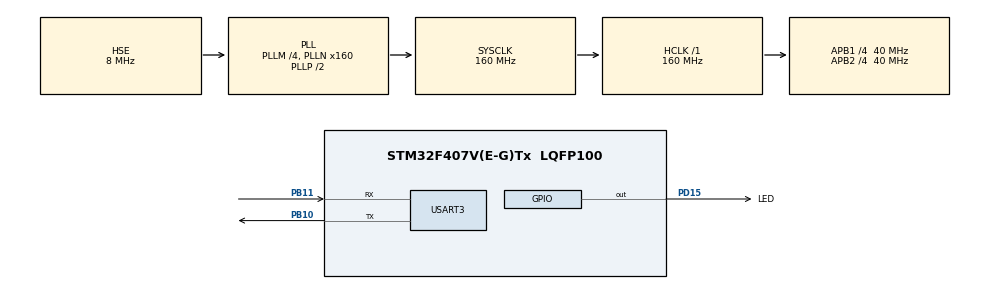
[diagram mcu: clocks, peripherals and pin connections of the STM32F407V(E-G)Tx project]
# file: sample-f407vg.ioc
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Mcu.Family=STM32F4
RCC.PLLSourceVirtual=RCC_PLLSOURCE_HSE
PH0-OSC_IN.Signal=RCC_OSC_IN
RCC.CortexFreq_Value=160000000
PD15.GPIO_Label=LED
PB10.Mode=Asynchronous
RTC.WakeUpClock=RTC_WAKEUPCLOCK_CK_SPRE_16BITS
NVIC.RTC_WKUP_IRQn=true\:1\:0\:true\:false\:true\:true\:true
VP_RTC_VS_RTC_Activate.Mode=RTC_Enabled
RCC.APB1CLKDivider=RCC_HCLK_DIV4
PB11.Signal=USART3_RX
RCC.SYSCLKSource=RCC_SYSCLKSOURCE_PLLCLK
ProjectManager.StackSize=0x400
PA13.Signal=SYS_JTMS-SWDIO
PB11.Mode=Asynchronous
ProjectManager.TargetToolchain=Makefile
RCC.HCLKFreq_Value=160000000
RCC.APB2TimFreq_Value=80000000
RTC.Format=RTC_FORMAT_BIN
RCC.LSE_VALUE=32768
RCC.AHBFreq_Value=160000000
PH0-OSC_IN.Mode=HSE-External-Oscillator
PB10.Signal=USART3_TX
RCC.HSE_VALUE=8000000
board=custom
RCC.VCOOutputFreq_Value=320000000
RCC.APB2Freq_Value=40000000
PA14.Mode=Serial_Wire
PH1-OSC_OUT.Signal=RCC_OSC_OUT
PA13.Mode=Serial_Wire
Mcu.Name=STM32F407V(E-G)Tx
PH1-OSC_OUT.Mode=HSE-External-Oscillator
RCC.48MHZClocksFreq_Value=80000000
RCC.SYSCLKFreq_VALUE=160000000
Mcu.Package=LQFP100
USART3.VirtualMode=VM_ASYNC
PA14.Signal=SYS_JTCK-SWCLK
VP_RTC_VS_RTC_Calendar.Mode=RTC_Calendar
ProjectManager.HeapSize=0x200
RCC.HSI_VALUE=16000000
VP_RTC_VS_RTC_WakeUp_intern.Mode=WakeUp
NVIC.PriorityGroup=NVIC_PRIORITYGROUP_4
RCC.APB2CLKDivider=RCC_HCLK_DIV4
RCC.PLLM=4
RCC.PLLN=160
RCC.APB1TimFreq_Value=80000000
RCC.APB1Freq_Value=40000000
PD15.Signal=GPIO_Output

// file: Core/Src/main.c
/* USER CODE BEGIN Header */
/**
 ******************************************************************************
 * @file           : main.c
 * @brief          : Main program body
 ******************************************************************************
 * @attention
 *
 * <h2><center>&copy; Copyright (c) 2021 STMicroelectronics.
 * All rights reserved.</center></h2>
 *
 * This software component is licensed by ST under BSD 3-Clause license,
 * the "License"; You may not use this file except in compliance with the
 * License. You may obtain a copy of the License at:
 *                        opensource.org/licenses/BSD-3-Clause
 *
 ******************************************************************************
 */
/* USER CODE END Header */
#include "main.h"

RTC_HandleTypeDef hrtc;

UART_HandleTypeDef huart3;

/* USER CODE BEGIN PV */
#include <stdio.h>
#include <stdint.h>
#include "PROJECT/project.h"
/* USER CODE END PV */

void SystemClock_Config(void);
static void MX_GPIO_Init(void);
static void MX_RTC_Init(void);
static void MX_USART3_UART_Init(void);
/* USER CODE BEGIN PFP */

void HAL_RTCEx_WakeUpTimerEventCallback(RTC_HandleTypeDef* hrtc)
{
  HAL_GPIO_TogglePin(LED_GPIO_Port, LED_Pin);
}

/* USER CODE END PFP */

int main(void)
{

    /* MCU Configuration--------------------------------------------------------*/

    /* Reset of all peripherals, Initializes the Flash interface and the Systick.
     */
    HAL_Init();

    /* Configure the system clock */
    SystemClock_Config();

    /* Initialize all configured peripherals */
    MX_GPIO_Init();
    MX_RTC_Init();
    MX_USART3_UART_Init();

    /* Infinite loop */
    /* USER CODE BEGIN WHILE */
    char str[20];
    RTC_TimeTypeDef sTime;
    RTC_DateTypeDef sDate;
    int a;
    while (1)
    {
        HAL_RTC_GetTime(&hrtc, &sTime, RTC_FORMAT_BIN);
        HAL_RTC_GetDate(&hrtc, &sDate, RTC_FORMAT_BIN);
        size_t const length = sprintf(str, "%2.2u:%2.2u:%2.2u\n", sTime.Hours, sTime.Minutes, sTime.Seconds);
        sendTextUart(str, length);
        HAL_Delay(1000);
        /* USER CODE END WHILE */

    }
}

void SystemClock_Config(void)
{
    RCC_OscInitTypeDef RCC_OscInitStruct = {0};
    RCC_ClkInitTypeDef RCC_ClkInitStruct = {0};
    RCC_PeriphCLKInitTypeDef PeriphClkInitStruct = {0};

    /** Configure the main internal regulator output voltage
     */
    __HAL_RCC_PWR_CLK_ENABLE();
    __HAL_PWR_VOLTAGESCALING_CONFIG(PWR_REGULATOR_VOLTAGE_SCALE1);
    /** Initializes the RCC Oscillators according to the specified parameters
     * in the RCC_OscInitTypeDef structure.
     */
    RCC_OscInitStruct.OscillatorType = RCC_OSCILLATORTYPE_LSI | RCC_OSCILLATORTYPE_HSE;
    RCC_OscInitStruct.HSEState = RCC_HSE_ON;
    RCC_OscInitStruct.LSIState = RCC_LSI_ON;
    RCC_OscInitStruct.PLL.PLLState = RCC_PLL_ON;
    RCC_OscInitStruct.PLL.PLLSource = RCC_PLLSOURCE_HSE;
    RCC_OscInitStruct.PLL.PLLM = 4;
    RCC_OscInitStruct.PLL.PLLN = 160;
    RCC_OscInitStruct.PLL.PLLP = RCC_PLLP_DIV2;
    RCC_OscInitStruct.PLL.PLLQ = 4;
    if (HAL_RCC_OscConfig(&RCC_OscInitStruct) != HAL_OK)
    {
        Error_Handler();
    }
    /** Initializes the CPU, AHB and APB buses clocks
     */
    RCC_ClkInitStruct.ClockType =
        RCC_CLOCKTYPE_HCLK | RCC_CLOCKTYPE_SYSCLK | RCC_CLOCKTYPE_PCLK1 | RCC_CLOCKTYPE_PCLK2;
    RCC_ClkInitStruct.SYSCLKSource = RCC_SYSCLKSOURCE_PLLCLK;
    RCC_ClkInitStruct.AHBCLKDivider = RCC_SYSCLK_DIV1;
    RCC_ClkInitStruct.APB1CLKDivider = RCC_HCLK_DIV4;
    RCC_ClkInitStruct.APB2CLKDivider = RCC_HCLK_DIV4;

    if (HAL_RCC_ClockConfig(&RCC_ClkInitStruct, FLASH_LATENCY_5) != HAL_OK)
    {
        Error_Handler();
    }
    PeriphClkInitStruct.PeriphClockSelection = RCC_PERIPHCLK_RTC;
    PeriphClkInitStruct.RTCClockSelection = RCC_RTCCLKSOURCE_LSI;
    if (HAL_RCCEx_PeriphCLKConfig(&PeriphClkInitStruct) != HAL_OK)
    {
        Error_Handler();
    }
}

static void MX_RTC_Init(void)
{

    RTC_TimeTypeDef sTime = {0};
    RTC_DateTypeDef sDate = {0};

    /** Initialize RTC Only
     */
    hrtc.Instance = RTC;
    hrtc.Init.HourFormat = RTC_HOURFORMAT_24;
    hrtc.Init.AsynchPrediv = 127;
    hrtc.Init.SynchPrediv = 255;
    hrtc.Init.OutPut = RTC_OUTPUT_DISABLE;
    hrtc.Init.OutPutPolarity = RTC_OUTPUT_POLARITY_HIGH;
    hrtc.Init.OutPutType = RTC_OUTPUT_TYPE_OPENDRAIN;
    if (HAL_RTC_Init(&hrtc) != HAL_OK)
    {
        Error_Handler();
    }

    /** Initialize RTC and set the Time and Date
     */
    sTime.Hours = 0;
    sTime.Minutes = 0;
    sTime.Seconds = 0;
    sTime.DayLightSaving = RTC_DAYLIGHTSAVING_NONE;
    sTime.StoreOperation = RTC_STOREOPERATION_RESET;
    if (HAL_RTC_SetTime(&hrtc, &sTime, RTC_FORMAT_BIN) != HAL_OK)
    {
        Error_Handler();
    }
    sDate.WeekDay = RTC_WEEKDAY_MONDAY;
    sDate.Month = RTC_MONTH_JANUARY;
    sDate.Date = 1;
    sDate.Year = 0;

    if (HAL_RTC_SetDate(&hrtc, &sDate, RTC_FORMAT_BIN) != HAL_OK)
    {
        Error_Handler();
    }
    /** Enable the WakeUp
     */
    if (HAL_RTCEx_SetWakeUpTimer_IT(&hrtc, 0, RTC_WAKEUPCLOCK_CK_SPRE_16BITS) != HAL_OK)
    {
        Error_Handler();
    }
}

static void MX_USART3_UART_Init(void)
{

    huart3.Instance = USART3;
    huart3.Init.BaudRate = 115200;
    huart3.Init.WordLength = UART_WORDLENGTH_8B;
    huart3.Init.StopBits = UART_STOPBITS_1;
    huart3.Init.Parity = UART_PARITY_NONE;
    huart3.Init.Mode = UART_MODE_TX_RX;
    huart3.Init.HwFlowCtl = UART_HWCONTROL_NONE;
    huart3.Init.OverSampling = UART_OVERSAMPLING_16;
    if (HAL_UART_Init(&huart3) != HAL_OK)
    {
        Error_Handler();
    }
}

static void MX_GPIO_Init(void)
{
    GPIO_InitTypeDef GPIO_InitStruct = {0};

    /* GPIO Ports Clock Enable */
    __HAL_RCC_GPIOH_CLK_ENABLE();
    __HAL_RCC_GPIOB_CLK_ENABLE();
    __HAL_RCC_GPIOD_CLK_ENABLE();
    __HAL_RCC_GPIOA_CLK_ENABLE();

    /*Configure GPIO pin Output Level */
    HAL_GPIO_WritePin(LED_GPIO_Port, LED_Pin, GPIO_PIN_RESET);

    /*Configure GPIO pin : LED_Pin */
    GPIO_InitStruct.Pin = LED_Pin;
    GPIO_InitStruct.Mode = GPIO_MODE_OUTPUT_PP;
    GPIO_InitStruct.Pull = GPIO_NOPULL;
    GPIO_InitStruct.Speed = GPIO_SPEED_FREQ_LOW;
    HAL_GPIO_Init(LED_GPIO_Port, &GPIO_InitStruct);
}

void Error_Handler(void)
{
    __disable_irq();
    while (1)
    {
    }
}

#ifdef USE_FULL_ASSERT
/**
 * @brief  Reports the name of the source file and the source line number
 *         where the assert_param error has occurred.
 * @param  file: pointer to the source file name
 * @param  line: assert_param error line source number
 * @retval None
 */
void assert_failed(uint8_t* file, uint32_t line)
{
    /* USER CODE BEGIN 6 */
    /* User can add his own implementation to report the file name and line
       number,
       ex: printf("Wrong parameters value: file %s on line %d\r\n", file, line) */
    /* USER CODE END 6 */
}
#endif /* USE_FULL_ASSERT */

/************************ (C) COPYRIGHT STMicroelectronics *****END OF FILE****/
